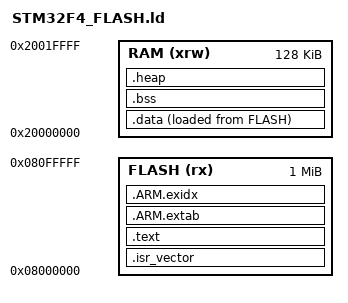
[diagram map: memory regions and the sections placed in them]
ENTRY(Reset_Handler)
/* Common subset of STM32F407VG and STM32F427VI memory. */
MEMORY {
  FLASH (rx) : ORIGIN = 0x08000000, LENGTH = 1024K
  RAM (xrw) : ORIGIN = 0x20000000, LENGTH = 128K
}
_estack = ORIGIN(RAM) + LENGTH(RAM);
SECTIONS {
  .isr_vector : { . = ALIGN(512); KEEP(*(.isr_vector)) } > FLASH
  .text : { *(.text*) *(.rodata*) . = ALIGN(4); } > FLASH
  .ARM.extab : { *(.ARM.extab*) } > FLASH
  .ARM.exidx : { *(.ARM.exidx*) } > FLASH
  _sidata = LOADADDR(.data);
  .data : { . = ALIGN(4); _sdata = .; *(.data*) . = ALIGN(4); _edata = .; } > RAM AT > FLASH
  .bss (NOLOAD) : { . = ALIGN(4); _sbss = .; *(.bss*) *(COMMON) . = ALIGN(4); _ebss = .; } > RAM
  .heap (NOLOAD) : { . = ALIGN(8); _heap_start = .; . += 8192; _heap_end = .; } > RAM
  ASSERT(_heap_end <= _estack - 8192, "RAM overflow: reserve 8 KiB main stack")
  /DISCARD/ : { *(.comment*) *(.note*) }
}
